# ARMv7M register map
Registers are read-write, no defined reset value unless marked. A register's access mark holds for its fields unless they carry their own. Offsets are from the block's base; [hi:lo] are bit positions; {n}, {i} and the like mark numbered series.

## ICB — Implementation Control Block
Base 0xE000E004
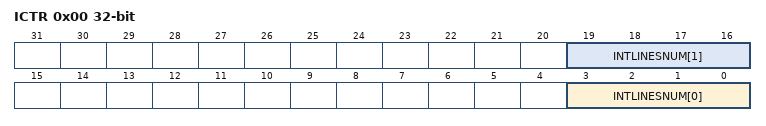
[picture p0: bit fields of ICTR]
0x00 ICTR ro — Interrupt Controller Type Register provides information about the interrupt controller
  [16n+3:16n] INTLINESNUM[{n}] (n=0..1) — The total number of interrupt lines supported by an implementation, defined in groups of 32
0x04 ACTLR — Auxiliary Control Register provides IMPLEMENTATION DEFINED configuration and control options

## SYSTICK — SysTick Timer
Base 0xE000E010
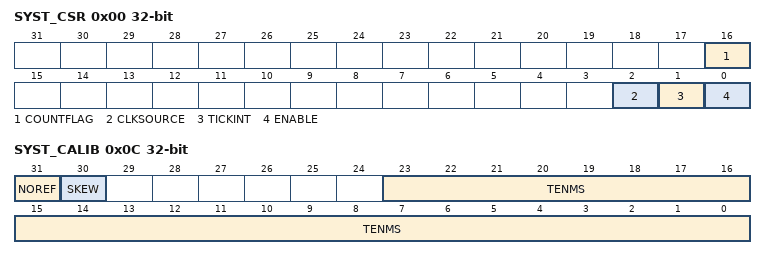
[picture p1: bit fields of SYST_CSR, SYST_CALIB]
0x00 SYST_CSR — SysTick Control and Status Register controls the system timer and provides status data
  [16] COUNTFLAG — Indicates whether the counter has counted to 0 since the last read of this register
    0=Timer has not counted to 0; 1=Timer has counted to 0
  [2] CLKSOURCE — Indicates the SysTick clock source
    0=SysTick uses the IMPLEMENTATION DEFINED external reference clock; 1=SysTick uses the processor clock
  [1] TICKINT — Indicates whether counting to 0 causes the status of the SysTick exception to change to pending
    0=Count to 0 does not affect the SysTick exception status; 1=Count to 0 changes the SysTick exception status to pending
  [0] ENABLE — Indicates the enabled status of the SysTick counter
    0=Counter is disabled; 1=Counter is operating
0x04 SYST_RVR — SysTick Reload Value Register holds the reload value of the SYST_CVR
  [23:0] RELOAD — The value to load into the SYST_CVR when the counter reaches 0
0x08 SYST_CVR — SysTick Current Value Register reads or clears the current counter value
  [31:0] CURRENT — Current counter value
0x0C SYST_CALIB ro — SysTick Calibration value Register reads the calibration value and parameters for SysTick
  [31] NOREF — Indicates whether the IMPLEMENTATION DEFINED reference clock is implemented
    0=The reference clock is implemented; 1=The reference clock is not implemented
  [30] SKEW — Indicates whether the 10ms calibration value is exact
    0=10ms calibration value is exact; 1=10ms calibration value is inexact, because of the clock frequency
  [23:0] TENMS — Optionally, holds a reload value to be used for 10ms (100Hz) timing, subject to system clock skew errors

## MPU — Memory Protection Unit
Base 0xE000ED90
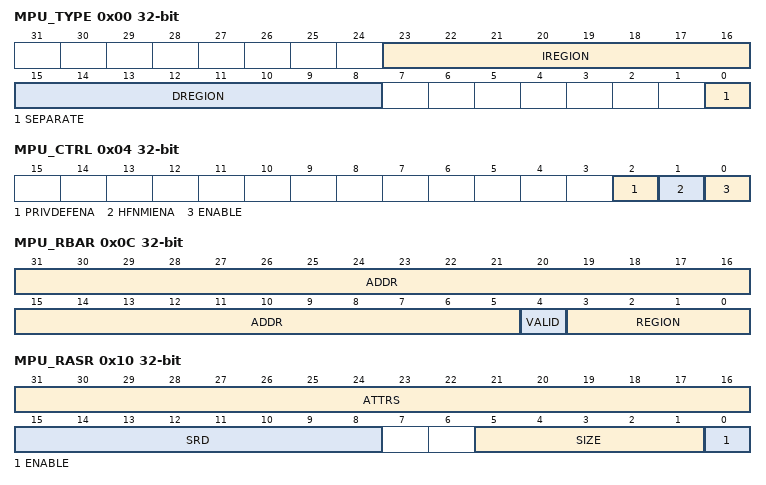
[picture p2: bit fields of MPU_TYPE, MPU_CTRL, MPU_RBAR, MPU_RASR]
0x00 MPU_TYPE ro — MPU Type Register the MPU Type Register indicates how many regions the MPU support
  [23:16] IREGION — Instruction region
  [15:8] DREGION — Number of regions supported by the MPU
  [0] SEPARATE — Indicates support for separate instruction and data address maps. RAZ. ARMv7-M only supports a unified MPU
0x04 MPU_CTRL — MPU Control Register enables the MPU, and when the MPU is enabled, controls whether the default memory map is enabled as a background region for privileged accesses, and whether the MPU is enabled for HardFaults, NMIs
  [2] PRIVDEFENA — When the ENABLE bit is set to 1, the meaning of this bit is
    0=Disables the default memory map; 1=Enables the default memory map as a background region for privileged access
  [1] HFNMIENA — When the ENABLE bit is set to 1, controls whether handlers executing with priority less than 0 access memory with the MPU enabled or with the MPU disabled
    0=Disables the MPU for these handlers; 1=Use the MPU for memory accesses by these handlers
  [0] ENABLE — Enables the MPU
    0=The MPU is disabled; 1=The MPU is enabled
0x08 MPU_RNR — MPU Region Number Register selects the region currently accessed by MPU_RBAR and MPU_RASR
  [7:0] REGION — Indicates the memory region accessed by MPU_RBAR and MPU_RASR
0x0C MPU_RBAR — MPU Region Base Address Register holds the base address of the region identified by MPU_RNR
  [31:5] ADDR — Base address of the region
  [4] VALID — On writes, indicates whether the region to update is specified by MPU_RNR
    0=Apply the base address update to the region specified by MPU_RNR.REGION; 1=Update MPU_RNR.REGION to the value obtained by zero extending the REGION value specified in this write
  [3:0] REGION — On writes, can specify the number of the region to update
0x10 MPU_RASR — MPU Region Attribute and Size Register defines the size and access behavior of the region identified by MPU_RNR, and enables that region
  [31:16] ATTRS — The MPU Region Attribute field
  [15:8] SRD — Subregion Disable
    0=Subregion enabled; 1=Subregion disabled
  [5:1] SIZE — Indicates the region size
  [0] ENABLE — Enables this region
    0=When the MPU is enabled, this region is disabled; 1=When the MPU is enabled, this region is enabled

## SIG — Software Interrupt Generation
Base 0xE000EF00
0x00 STIR wo — Software Triggered Interrupt Register provides a mechanism for software to generate an interrupt
  [8:0] INTID — Indicates the interrupt to be triggered

## TPIU — Trace Port Interface Unit
Base 0xE0040000
0x00 TPIU_SSPSR ro — Supported Parallel Port Sizes Register indicates the supported parallel trace port sizes
  [31:0] SWIDTH[31:0] — SWIDTH[N] represents a trace port width of (N+1)
    0=Width (N+1) not supported; 1=Width (N+1) supported
0x04 TPIU_CSPSR — Current Parallel Port Size Register defines the width of the current parallel trace port
  [31:0] CWIDTH[31:0] — CWIDTH[N] represents a trace port width of (N+1)
    0=Width (N+1) is not the current trace port width; 1=Width (N+1) is the current trace port width
0x10 TPIU_ACPR — Asynchronous Clock Prescaler Register defines a prescaler value for the baud rate of the Serial Wire Output (SWO)
  [15:0] SWOSCALER — SWO baud rate prescaler value
0xF0 TPIU_SPPR — Selected Pin Protocol Register selects the protocol used for trace output
  [1:0] TXMODE — Specifies the protocol for trace output from the TPIU
    0=Parallel trace port mode; 1=Asynchronous SWO, using Manchester encoding; 2=Asynchronous SWO, using NRZ encoding
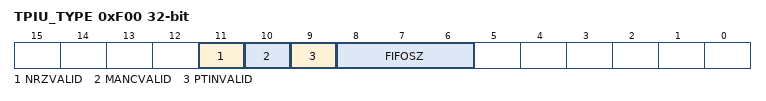
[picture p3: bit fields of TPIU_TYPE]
0xF00 TPIU_TYPE ro — TPIU Type register defines the SWO options supported by the TPIU
  [11] NRZVALID — Indicates support for SWO using UART/NRZ encoding
    0=Not supported; 1=Supported
  [10] MANCVALID — Indicates support for SWO using Manchester encoding
    0=Not supported; 1=Supported
  [9] PTINVALID — Indicates support for parallel trace port operation
    0=Supported; 1=Not supported
  [8:6] FIFOSZ — Indicates the minimum implemented size of the TPIU output FIFO for trace data
